# ESP32-H4 register map
Vendor: ESPRESSIF SYSTEMS (SHANGHAI) CO., LTD.; Series: ESP32 H-Series; File version: 1
CPU: RV32IMAC r0p0, little endian, no MPU, no FPU, 0 interrupt priority bits
Address unit: 32 bits
Registers are 32-bit, read-write, reset 0x0 unless marked. A register's access mark holds for its fields unless they carry their own. Offsets are from the block's base; [hi:lo] are bit positions; {n}, {i} and the like mark numbered series; 'fields as' and 'values as' point back to an identical list; <NAME> marks a mode.

## GPIO — General Purpose Input/Output
Base 0x60093000
0x00 STRAP ro — Strapping pin register
  [15:0] STRAPPING — Represents the values of GPIO strapping pins. (need update the description, for example) - bit0: invalid - bit1: MTMS - bit2: MTDI - bit3: GPIO27 - bit4: GPIO28 - bit5: GPIO7 - bit6 ~ bit15: invalid
0x04 OUT — GPIO output register
  [31:0] DATA_ORIG — Configures the output value of GPIO0 ~ 31 output in simple GPIO output mode.\\ 0: Low level\\ 1: High level\\ The value of bit0 ~ bit31 correspond to the output value of GPIO0 ~ GPIO31 respectively. Bitxx ~ bitxx is invalid.\\
0x08 OUT_W1TS wo — GPIO output set register
  [31:0] OUT_W1TS — Configures whether or not to set the output register GPIO_OUT_REG of GPIO0 ~ GPIO31.\\ 0: Not set\\ 1: The corresponding bit in GPIO_OUT_REG will be set to 1\\ Bit0 ~ bit31 are corresponding to GPIO0 ~ GPIO31. Bitxx ~ bitxx is invalid. \\ Recommended operation: use this register to set GPIO_OUT_REG. \\
0x0C OUT_W1TC wo — GPIO output clear register
  [31:0] OUT_W1TC — Configures whether or not to clear the output register GPIO_OUT_REG of GPIO0 ~ GPIO31 output.\\ 0: Not clear\\ 1: The corresponding bit in GPIO_OUT_REG will be cleared.\\ Bit0 ~ bit31 are corresponding to GPIO0 ~ GPIO31. Bitxx ~ bitxx is invalid. \\ Recommended operation: use this register to clear GPIO_OUT_REG. \\
0x10 OUT1 — GPIO output register
  [11:0] DATA_ORIG — Configures the output value of GPIO32 ~ 43 output in simple GPIO output mode.\\ 0: Low level\\ 1: High level\\ The value of bit32 ~ bit43 correspond to the output value of GPIO32 ~ GPIO43 respectively. Bitxx ~ bitxx is invalid.\\
0x14 OUT1_W1TS wo — GPIO output set register
  [11:0] OUT1_W1TS — Configures whether or not to set the output register GPIO_OUT1_REG of GPIO32 ~ GPIO43.\\ 0: Not set\\ 1: The corresponding bit in GPIO_OUT1_REG will be set to 1\\ Bit32 ~ bit43 are corresponding to GPIO32 ~ GPIO43. Bitxx ~ bitxx is invalid. \\ Recommended operation: use this register to set GPIO_OUT1_REG. \\
0x18 OUT1_W1TC wo — GPIO output clear register
  [11:0] OUT1_W1TC — Configures whether or not to clear the output register GPIO_OUT1_REG of GPIO32 ~ GPIO43 output.\\ 0: Not clear\\ 1: The corresponding bit in GPIO_OUT1_REG will be cleared.\\ Bit32 ~ bit43 are corresponding to GPIO32 ~ GPIO43. Bitxx ~ bitxx is invalid. \\ Recommended operation: use this register to clear GPIO_OUT1_REG. \\
0x34 ENABLE — GPIO output enable register
  [31:0] DATA — Configures whether or not to enable the output of GPIO0 ~ GPIO31.\\ 0: Not enable\\ 1: Enable\\ Bit0 ~ bit31 are corresponding to GPIO0 ~ GPIO31. Bitxx ~ bitxx is invalid.\\
0x38 ENABLE_W1TS wo — GPIO output enable set register
  [31:0] ENABLE_W1TS — Configures whether or not to set the output enable register GPIO_ENABLE_REG of GPIO0 ~ GPIO31.\\ 0: Not set\\ 1: The corresponding bit in GPIO_ENABLE_REG will be set to 1\\ Bit0 ~ bit31 are corresponding to GPIO0 ~ GPIO31. Bitxx ~ bitxx is invalid. \\ Recommended operation: use this register to set GPIO_ENABLE_REG.\\
0x3C ENABLE_W1TC wo — GPIO output enable clear register
  [31:0] ENABLE_W1TC — Configures whether or not to clear the output enable register GPIO_ENABLE_REG of GPIO0 ~ GPIO31. \\ 0: Not clear\\ 1: The corresponding bit in GPIO_ENABLE_REG will be cleared\\ Bit0 ~ bit31 are corresponding to GPIO0 ~ GPIO31. Bitxx ~ bitxx is invalid. \\ Recommended operation: use this register to clear GPIO_ENABLE_REG.\\
0x40 ENABLE1 — GPIO output enable register
  [11:0] DATA — Configures whether or not to enable the output of GPIO32 ~ GPIO43.\\ 0: Not enable\\ 1: Enable\\ Bit32 ~ bit43 are corresponding to GPIO32 ~ GPIO43. Bitxx ~ bitxx is invalid.\\
0x44 ENABLE1_W1TS wo — GPIO output enable set register
  [11:0] ENABLE1_W1TS — Configures whether or not to set the output enable register GPIO_ENABLE1_REG of GPIO32 ~ GPIO43.\\ 0: Not set\\ 1: The corresponding bit in GPIO_ENABLE1_REG will be set to 1\\ Bit32 ~ bit43 are corresponding to GPIO32 ~ GPIO43. Bitxx ~ bitxx is invalid. \\ Recommended operation: use this register to set GPIO_ENABLE1_REG.\\
0x48 ENABLE1_W1TC wo — GPIO output enable clear register
  [11:0] ENABLE1_W1TC — Configures whether or not to clear the output enable register GPIO_ENABLE1_REG of GPIO32 ~ GPIO43. \\ 0: Not clear\\ 1: The corresponding bit in GPIO_ENABLE1_REG will be cleared\\ Bit32 ~ bit43 are corresponding to GPIO32 ~ GPIO43. Bitxx ~ bitxx is invalid. \\ Recommended operation: use this register to clear GPIO_ENABLE1_REG.\\
0x64 IN ro — GPIO input register
  [31:0] DATA_NEXT — Represents the input value of GPIO0 ~ GPIO31. Each bit represents a pin input value:\\ 0: Low level\\ 1: High level\\ Bit0 ~ bit31 are corresponding to GPIO0 ~ GPIO31. Bitxx ~ bitxx is invalid.\\
0x68 IN1 ro — GPIO input register
  [11:0] DATA_NEXT — Represents the input value of GPIO32 ~ GPIO43. Each bit represents a pin input value:\\ 0: Low level\\ 1: High level\\ Bit32 ~ bit43 are corresponding to GPIO32 ~ GPIO43. Bitxx ~ bitxx is invalid.\\
0x74 STATUS — GPIO interrupt status register
  [31:0] INTERRUPT — The interrupt status of GPIO0 ~ GPIO31, can be configured by the software. - Bit0 ~ bit31 are corresponding to GPIO0 ~ GPIO31. Bitxx ~ bitxx is invalid. - Each bit represents the status of its corresponding GPIO: - 0: Represents the GPIO does not generate the interrupt configured by GPIO_PIN0_INT_TYPE, or this bit is configured to 0 by the software. - 1: Represents the GPIO generates the interrupt configured by GPIO_PIN0_INT_TYPE, or this bit is configured to 1 by the software.
0x78 STATUS_W1TS wo — GPIO interrupt status set register
  [31:0] STATUS_W1TS — Configures whether or not to set the interrupt status register GPIO_STATUS_INTERRUPT of GPIO0 ~ GPIO31. - Bit0 ~ bit31 are corresponding to GPIO0 ~ GPIO31. Bitxx ~ bitxx is invalid. - If the value 1 is written to a bit here, the corresponding bit in GPIO_STATUS_INTERRUPT will be set to 1. \item Recommended operation: use this register to set GPIO_STATUS_INTERRUPT.
0x7C STATUS_W1TC wo — GPIO interrupt status clear register
  [31:0] STATUS_W1TC — Configures whether or not to clear the interrupt status register GPIO_STATUS_INTERRUPT of GPIO0 ~ GPIO31. - Bit0 ~ bit31 are corresponding to GPIO0 ~ GPIO31. Bitxx ~ bitxx is invalid. - If the value 1 is written to a bit here, the corresponding bit in GPIO_STATUS_INTERRUPT will be cleared. \item Recommended operation: use this register to clear GPIO_STATUS_INTERRUPT.
0x80 STATUS1 — GPIO interrupt status register
  [11:0] INTERRUPT — The interrupt status of GPIO32 ~ GPIO43, can be configured by the software. - Bit32 ~ bit43 are corresponding to GPIO32 ~ GPIO43. Bitxx ~ bitxx is invalid. - Each bit represents the status of its corresponding GPIO: - 0: Represents the GPIO does not generate the interrupt configured by GPIO_PIN0_INT_TYPE, or this bit is configured to 0 by the software. - 1: Represents the GPIO generates the interrupt configured by GPIO_PIN0_INT_TYPE, or this bit is configured to 1 by the software.
0x84 STATUS1_W1TS wo — GPIO interrupt status set register
  [11:0] STATUS1_W1TS — Configures whether or not to set the interrupt status register GPIO_STATUS1_INTERRUPT of GPIO32 ~ GPIO43. - Bit32 ~ bit43 are corresponding to GPIO32 ~ GPIO43. Bitxx ~ bitxx is invalid. - If the value 1 is written to a bit here, the corresponding bit in GPIO_STATUS1_INTERRUPT will be set to 1. \item Recommended operation: use this register to set GPIO_STATUS1_INTERRUPT.
0x88 STATUS1_W1TC wo — GPIO interrupt status clear register
  [11:0] STATUS1_W1TC — Configures whether or not to clear the interrupt status register GPIO_STATUS1_INTERRUPT of GPIO32 ~ GPIO43. - Bit32 ~ bit43 are corresponding to GPIO32 ~ GPIO43. Bitxx ~ bitxx is invalid. - If the value 1 is written to a bit here, the corresponding bit in GPIO_STATUS1_INTERRUPT will be cleared. \item Recommended operation: use this register to clear GPIO_STATUS1_INTERRUPT.
0xA4 PROCPU_INT ro — GPIO_PROCPU_INT interrupt status register
  [31:0] PROCPU_INT — Represents the GPIO_PROCPU_INT interrupt status of GPIO0 ~ GPIO31. Each bit represents:(need update in different project)\\ 0: Represents GPIO_PROCPU_INT interrupt is not enabled, or the GPIO does not generate the interrupt configured by GPIO_PIN0_INT_TYPE.\\ 1: Represents the GPIO generates an interrupt configured by GPIO_PIN0_INT_TYPE after the GPIO_PROCPU_INT interrupt is enabled.\\ Bit0 ~ bit31 are corresponding to GPIO0 ~ GPIO31. Bitxx ~ bitxx is invalid. This interrupt status is corresponding to the bit in GPIO_STATUS_REG when assert (high) enable signal (bit13 of GPIO_PIN0_REG). \\
0xA8 INTERRUPT_2 ro — GPIO_INTERRUPT_2 interrupt status register
  [31:0] INTERRUPT_2 — Represents the GPIO_INTERRUPT_2 interrupt status of GPIO0 ~ GPIO31. Each bit represents:(need update in different project)\\ 0: Represents GPIO_INTERRUPT_2 interrupt is not enabled, or the GPIO does not generate the interrupt configured by GPIO_PIN0_INT_TYPE.\\ 1: Represents the GPIO generates an interrupt configured by GPIO_PIN0_INT_TYPE after the GPIO_INTERRUPT_2 interrupt is enabled.\\ Bit0 ~ bit31 are corresponding to GPIO0 ~ GPIO31. Bitxx ~ bitxx is invalid. This interrupt status is corresponding to the bit in GPIO_STATUS_REG when assert (high) enable signal (bit13 of GPIO_PIN0_REG). \\
0xAC PROCPU_INT1 ro — GPIO_PROCPU_INT interrupt status register
  [11:0] PROCPU_INT1 — Represents the GPIO_PROCPU_INT interrupt status of GPIO32 ~ GPIO43. Each bit represents:(need update in different project)\\ 0: Represents GPIO_PROCPU_INT interrupt is not enabled, or the GPIO does not generate the interrupt configured by GPIO_PIN0_INT_TYPE.\\ 1: Represents the GPIO generates an interrupt configured by GPIO_PIN0_INT_TYPE after the GPIO_PROCPU_INT interrupt is enabled.\\ Bit32 ~ bit43 are corresponding to GPIO32 ~ GPIO43. Bitxx ~ bitxx is invalid. This interrupt status is corresponding to the bit in GPIO_STATUS1_REG when assert (high) enable signal (bit13 of GPIO_PIN0_REG). \\
0xB0 INTERRUPT_21 ro — GPIO_INTERRUPT_2 interrupt status register
  [11:0] INTERRUPT_21 — Represents the GPIO_INTERRUPT_2 interrupt status of GPIO32 ~ GPIO43. Each bit represents:(need update in different project)\\ 0: Represents GPIO_INTERRUPT_2 interrupt is not enabled, or the GPIO does not generate the interrupt configured by GPIO_PIN0_INT_TYPE.\\ 1: Represents the GPIO generates an interrupt configured by GPIO_PIN0_INT_TYPE after the GPIO_INTERRUPT_2 interrupt is enabled.\\ Bit32 ~ bit43 are corresponding to GPIO32 ~ GPIO43. Bitxx ~ bitxx is invalid. This interrupt status is corresponding to the bit in GPIO_STATUS1_REG when assert (high) enable signal (bit13 of GPIO_PIN0_REG). \\
0xC4 STATUS_NEXT ro — GPIO interrupt source register
  [31:0] STATUS_INTERRUPT_NEXT — Represents the interrupt source signal of GPIO0 ~ GPIO31.\\ Bit0 ~ bit24 are corresponding to GPIO0 ~ GPIO31. Bitxx ~ bitxx is invalid. Each bit represents:\\ 0: The GPIO does not generate the interrupt configured by GPIO_PIN0_INT_TYPE.\\ 1: The GPIO generates an interrupt configured by GPIO_PIN0_INT_TYPE.\\ The interrupt could be rising edge interrupt, falling edge interrupt, level sensitive interrupt and any edge interrupt.\\
0xC8 STATUS_NEXT1 ro — GPIO interrupt source register
  [11:0] STATUS_INTERRUPT_NEXT1 — Represents the interrupt source signal of GPIO32 ~ GPIO43.\\ Bit0 ~ bit24 are corresponding to GPIO32 ~ GPIO43. Bitxx ~ bitxx is invalid. Each bit represents:\\ 0: The GPIO does not generate the interrupt configured by GPIO_PIN0_INT_TYPE.\\ 1: The GPIO generates an interrupt configured by GPIO_PIN0_INT_TYPE.\\ The interrupt could be rising edge interrupt, falling edge interrupt, level sensitive interrupt and any edge interrupt.\\
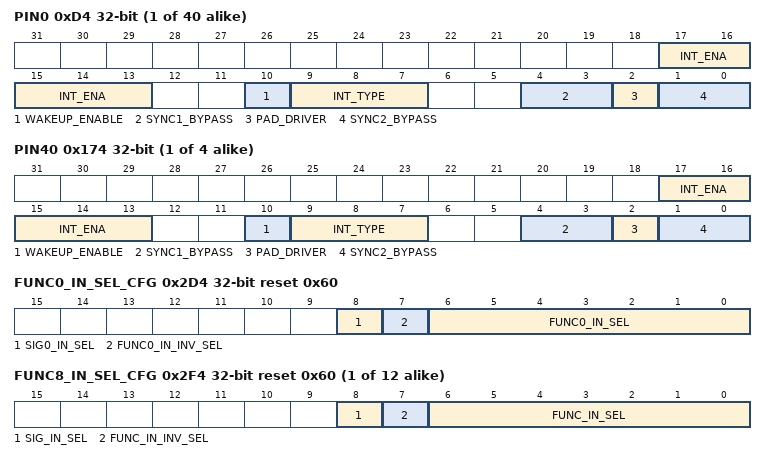
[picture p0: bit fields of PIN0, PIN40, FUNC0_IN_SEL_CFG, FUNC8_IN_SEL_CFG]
{0xD4+4i} PIN{i} (i=0..39) — GPIO{i} configuration register
  [17:13] INT_ENA — Configures whether or not to enable gpio_procpu_int or gpio_interrupt_2(need update in different project). - bit13: Configures whether or not to enable gpio_procpu_int(need update in different project):\\ 0: Disable\\ 1: Enable\\ - bit14: Configures whether or not to enable gpio_interrupt_2(need update in different project):\\ 0: Disable\\ 1: Enable\\ - bit15 ~ bit17: invalid
  [10] WAKEUP_ENABLE — Configures whether or not to enable GPIO wake-up function.\\ 0: Disable\\ 1: Enable\\ This function only wakes up the CPU from Light-sleep. \\
  [9:7] INT_TYPE — Configures GPIO interrupt type.\\ 0: GPIO interrupt disabled\\ 1: Rising edge trigger\\ 2: Falling edge trigger\\ 3: Any edge trigger\\ 4: Low level trigger\\ 5: High level trigger\\
  [4:3] SYNC1_BYPASS — Configures whether or not to synchronize GPIO input data on either edge of IO MUX operating clock for the first-level synchronization.\\ 0: Not synchronize\\ 1: Synchronize on falling edge\\ 2: Synchronize on rising edge\\ 3: Synchronize on rising edge\\
  [2] PAD_DRIVER — Configures to select pin drive mode. \\ 0: Normal output\\ 1: Open drain output \\
  [1:0] SYNC2_BYPASS — Configures whether or not to synchronize GPIO input data on either edge of IO MUX operating clock for the second-level synchronization.\\ 0: Not synchronize\\ 1: Synchronize on falling edge\\ 2: Synchronize on rising edge\\ 3: Synchronize on rising edge\\
{0xD4+4i} PIN{i} (i=40..43) — GPIO$n configuration register
  fields as PIN0
0x2D4 FUNC0_IN_SEL_CFG reset 0x60 — Configuration register for input signal 0
  [8] SIG0_IN_SEL — Configures whether or not to route signals via GPIO matrix.\\ 0: Bypass GPIO matrix, i.e., connect signals directly to peripheral configured in IO MUX.\\ 1: Route signals via GPIO matrix.\\
  [7] FUNC0_IN_INV_SEL — Configures whether or not to invert the input value.\\ 0: Not invert\\ 1: Invert\\
  [6:0] FUNC0_IN_SEL — Configures to select a pin from the 40 GPIO pins to connect the input signal 0.\\ 0: Select GPIO0\\ 1: Select GPIO1\\ ......\\ 38: Select GPIO38\\ 39: Select GPIO39\\ Or\\ 0x40: A constantly high input\\ 0x60: A constantly low input\\
{0x2D4+4i} FUNC{i}_IN_SEL_CFG (i=8..19) reset 0x60 — Configuration register for input signal {i}
  [8] SIG_IN_SEL — Configures whether or not to route signals via GPIO matrix.\\ 0: Bypass GPIO matrix, i.e., connect signals directly to peripheral configured in IO MUX.\\ 1: Route signals via GPIO matrix.\\
  [7] FUNC_IN_INV_SEL — Configures whether or not to invert the input value.\\ 0: Not invert\\ 1: Invert\\
  [6:0] FUNC_IN_SEL — Configures to select a pin from the 40 GPIO pins to connect the input signal %s.\\ 0: Select GPIO0\\ 1: Select GPIO1\\ ......\\ 38: Select GPIO38\\ 39: Select GPIO39\\ Or\\ 0x40: A constantly high input\\ 0x60: A constantly low input\\
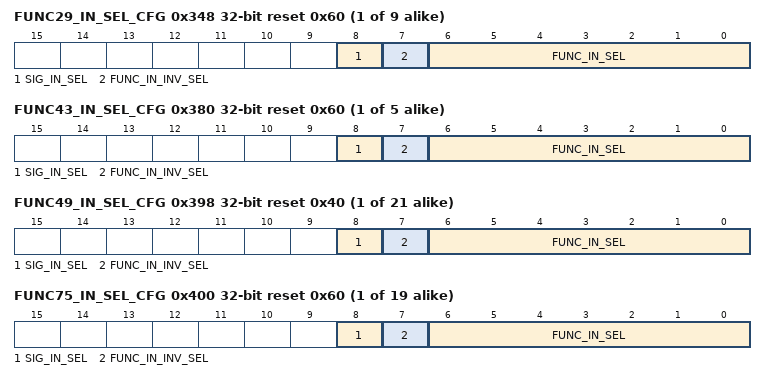
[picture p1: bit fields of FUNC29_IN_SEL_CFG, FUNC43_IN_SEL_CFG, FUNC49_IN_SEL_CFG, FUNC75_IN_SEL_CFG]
{0x2D4+4i} FUNC{i}_IN_SEL_CFG (i=29..37) reset 0x60 — Configuration register for input signal {i}
  fields as FUNC8_IN_SEL_CFG
{0x2D4+4i} FUNC{i}_IN_SEL_CFG (i=43..47) reset 0x60 — Configuration register for input signal {i}
  fields as FUNC8_IN_SEL_CFG
{0x2D4+4i} FUNC{i}_IN_SEL_CFG (i=49..69) reset 0x40 — Configuration register for input signal {i}
  fields as FUNC8_IN_SEL_CFG
{0x2D4+4i} FUNC{i}_IN_SEL_CFG (i=75..93) reset 0x60 — Configuration register for input signal {i}
  fields as FUNC8_IN_SEL_CFG
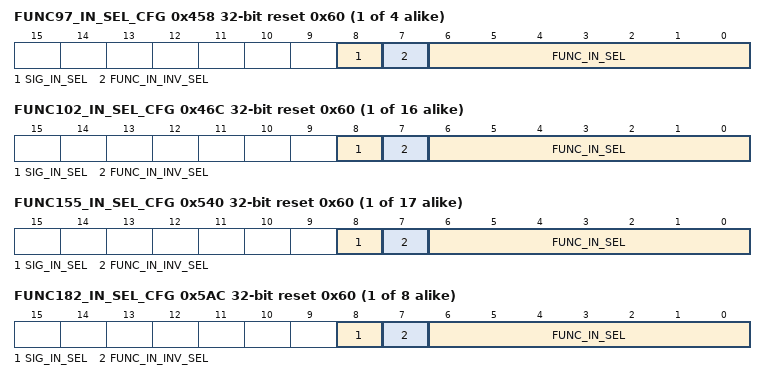
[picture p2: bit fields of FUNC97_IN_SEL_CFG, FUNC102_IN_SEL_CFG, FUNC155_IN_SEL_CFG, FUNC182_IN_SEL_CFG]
{0x2D4+4i} FUNC{i}_IN_SEL_CFG (i=97..100) reset 0x60 — Configuration register for input signal {i}
  fields as FUNC8_IN_SEL_CFG
{0x2D4+4i} FUNC{i}_IN_SEL_CFG (i=102..117) reset 0x60 — Configuration register for input signal {i}
  fields as FUNC8_IN_SEL_CFG
{0x2D4+4i} FUNC{i}_IN_SEL_CFG (i=155..171) reset 0x60 — Configuration register for input signal {i}
  fields as FUNC8_IN_SEL_CFG
{0x2D4+4i} FUNC{i}_IN_SEL_CFG (i=182..189) reset 0x60 — Configuration register for input signal {i}
  fields as FUNC8_IN_SEL_CFG
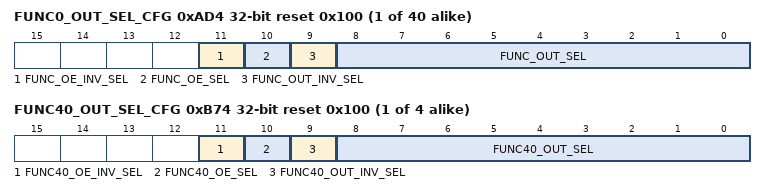
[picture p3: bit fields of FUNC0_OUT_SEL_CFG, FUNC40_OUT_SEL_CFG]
{0xAD4+4i} FUNC{i}_OUT_SEL_CFG (i=0..39) reset 0x100 — Configuration register for GPIO{i} output
  [11] FUNC_OE_INV_SEL — Configures whether or not to invert the output enable signal.\\ 0: Not invert\\ 1: Invert\\
  [10] FUNC_OE_SEL — Configures to select the source of output enable signal.\\ 0: Use output enable signal from peripheral.\\ 1: Force the output enable signal to be sourced from bit %s of GPIO_ENABLE_REG. \\
  [9] FUNC_OUT_INV_SEL — Configures whether or not to invert the output value.\\ 0: Not invert\\ 1: Invert\\
  [8:0] FUNC_OUT_SEL — Configures to select a signal 0 (0 <= 0 < 256) from 256 peripheral signals to be output from GPIO%s.\\ 0: Select signal 0\\ 1: Select signal 1\\ ......\\ 254: Select signal 254\\ 255: Select signal 255\\ Or\\ 256: Bit %s of GPIO_OUT_REG and GPIO_ENABLE_REG are selected as the output value and output enable. For the detailed signal list, see Table <a href=tab:iomuxgpio-periph-signals-via-gpio-matrix">link</a>. "
{0xAD4+4i} FUNC{i}_OUT_SEL_CFG reset 0x100 (i=40..43) — Configuration register for GPIO$n output
  [11] FUNC{i}_OE_INV_SEL — Configures whether or not to invert the output enable signal.\\ 0: Not invert\\ 1: Invert\\
  [10] FUNC{i}_OE_SEL — Configures to select the source of output enable signal.\\ 0: Use output enable signal from peripheral.\\ 1: Force the output enable signal to be sourced from bit 10 of GPIO_ENABLE_REG. \\
  [9] FUNC{i}_OUT_INV_SEL — Configures whether or not to invert the output value.\\ 0: Not invert\\ 1: Invert\\
  [8:0] FUNC{i}_OUT_SEL — Configures to select a signal 0 (0 <= 0 < 256) from 256 peripheral signals to be output from GPIO0.\\ 0: Select signal 0\\ 1: Select signal 1\\ ......\\ 254: Select signal 254\\ 255: Select signal 255\\ Or\\ 256: Bit 0 of GPIO_OUT_REG and GPIO_ENABLE_REG are selected as the output value and output enable. For the detailed signal list, see Table <a href=tab:iomuxgpio-periph-signals-via-gpio-matrix">link</a>. "
0xDF8 CLOCK_GATE reset 0x1 — GPIO clock gate register
  [0] CLK_EN — Configures whether or not to enable clock gate.\\ 0: Not enable\\ 1: Enable, the clock is free running. \\
0xDFC DATE reset 0x2411250 — GPIO version register
  [27:0] DATE — Version control register. \\
